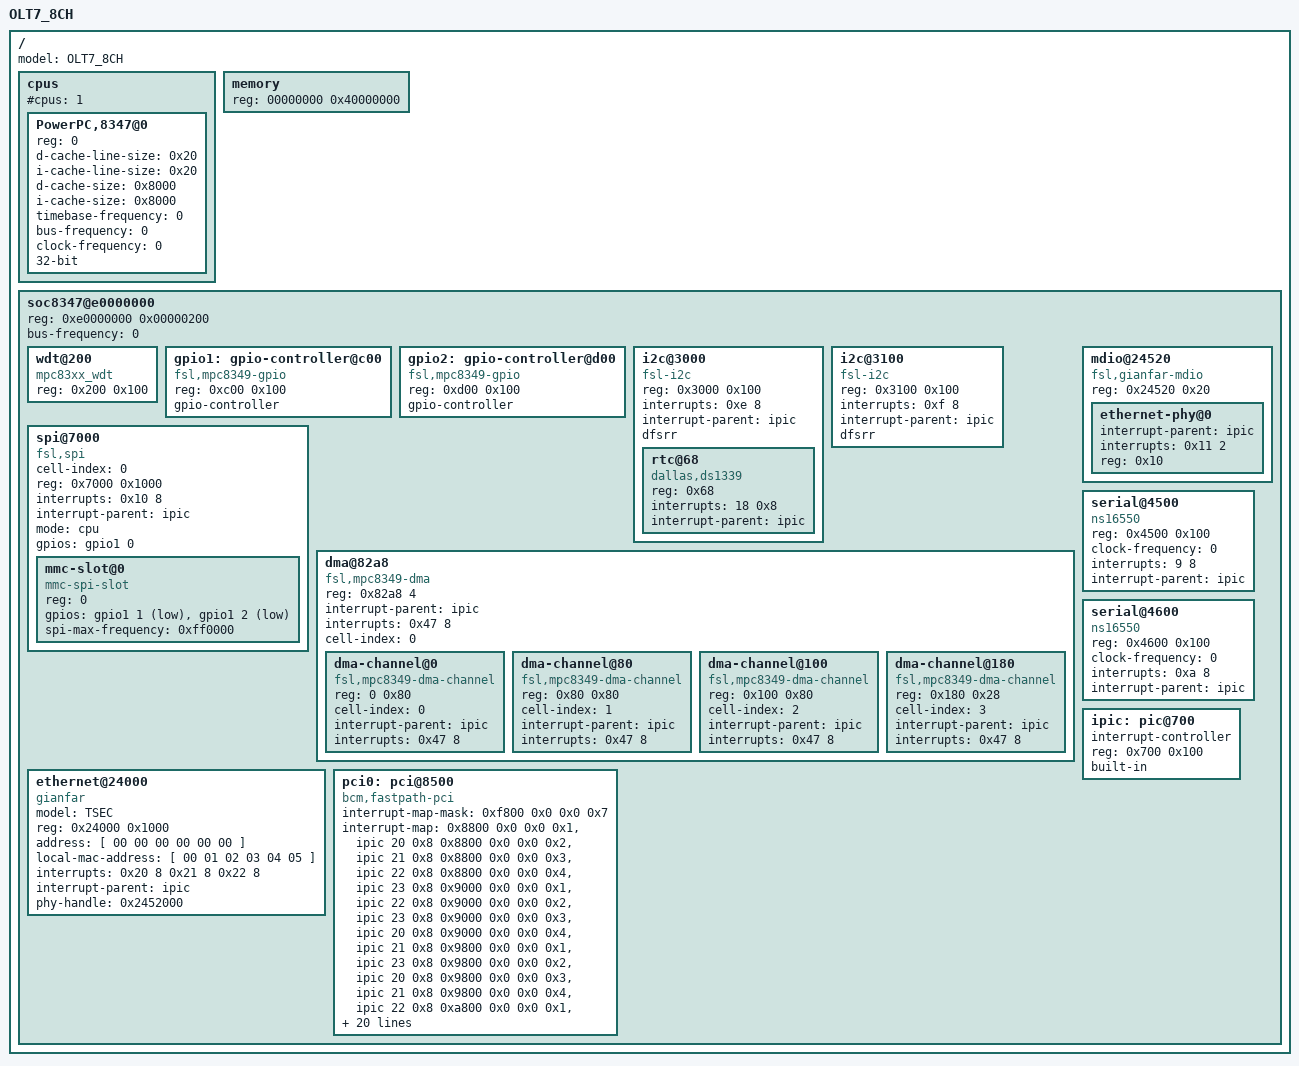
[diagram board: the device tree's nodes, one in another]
/*
 * OLT7_8CH Device Tree Source
 * Copyright 2011 PTInovacao,SA
 *
 * XXXX MPC8349E MDS Device Tree Source
 *
 * Copyright 2005, 2006 Freescale Semiconductor Inc.
 *
 * This program is free software; you can redistribute  it and/or modify it
 * under  the terms of  the GNU General  Public License as published by the
 * Free Software Foundation;  either version 2 of the  License, or (at your
 * option) any later version.
 */

 /dts-v1/;

/ {
	model = "OLT7_8CH";
//	compatible = "MPC834xMDS";
	#address-cells = <1>;
	#size-cells = <1>;

	cpus {
		#cpus = <1>;
		#address-cells = <1>;
		#size-cells = <0>;

		PowerPC,8347@0 {
			device_type = "cpu";
			reg = <0>;
			d-cache-line-size = <0x20>;	// 32 bytes
			i-cache-line-size = <0x20>;	// 32 bytes
			d-cache-size = <0x8000>;		// L1, 32K
			i-cache-size = <0x8000>;		// L1, 32K
			timebase-frequency = <0>;	// from bootloader
			bus-frequency = <0>;		// from bootloader
			clock-frequency = <0>;		// from bootloader
			32-bit;
		};
	};

	memory {
		device_type = "memory";
		reg = <00000000 0x40000000>;	// 512MB at 0
	};

	soc8347@e0000000 {
		#address-cells = <1>;
		#size-cells = <1>;
		#interrupt-cells = <2>;
		device_type = "soc";
		ranges = <0 0xe0000000 0x00100000>;
		reg = <0xe0000000 0x00000200>;
		bus-frequency = <0>;

		wdt@200 {
			device_type = "watchdog";
			compatible = "mpc83xx_wdt";
			reg = <0x200 0x100>;
		};

	        gpio1: gpio-controller@c00 {
                        #gpio-cells = <2>;
                        compatible = "fsl,mpc8349-gpio";
                        reg = <0xc00 0x100>;
//                        interrupts = <0x4a 8>;
//                        interrupt-parent = <&ipic>;
                        gpio-controller;
                };

                gpio2: gpio-controller@d00 {
                        #gpio-cells = <2>;
                        compatible = "fsl,mpc8349-gpio";
                        reg = <0xd00 0x100>;
//                        interrupts = <0x4b 8>;
//                        interrupt-parent = <&ipic>;
                        gpio-controller;
                };

		i2c@3000 {
			device_type = "i2c";
			compatible = "fsl-i2c";
			reg = <0x3000 0x100>;
			interrupts = <0xe 8>;
			interrupt-parent = <&ipic>;
			dfsrr;


			rtc@68 {
				device_type = "rtc";
				compatible = "dallas,ds1339";
				reg = <0x68>;
				interrupts = <18 0x8>;
				interrupt-parent = <&ipic>;
			};


		};

		i2c@3100 {
			device_type = "i2c";
			compatible = "fsl-i2c";
			reg = <0x3100 0x100>;
			interrupts = <0xf 8>;
			interrupt-parent = <&ipic>;
			dfsrr;

//			dtt@48 {
//                                compatible = "dallas,ds75";
//                                reg = <0x48>;
//                        };
		};

		spi@7000 {
			#address-cells = <1>;
            		#size-cells = <0>;
            		cell-index = <0>;  
			device_type = "spi";
			compatible = "fsl,spi";
			reg = <0x7000 0x1000>;
			interrupts = <0x10 8>;
			interrupt-parent = <&ipic>;
			mode = "cpu";
			gpios = <&gpio1 0 0>;
			mmc-slot@0 {
                                compatible = "mmc-spi-slot";
                                reg = <0>;
                                gpios = <&gpio1 1 1
                                         &gpio1 2 1>;
//                                voltage-ranges = <3300 3300>;
//                                spi-max-frequency = <2faf080>;
                                spi-max-frequency = <0xff0000>;
                        };

		};

		dma@82a8 {
			#address-cells = <1>;
			#size-cells = <1>;
			compatible = "fsl,mpc8349-dma", "fsl,elo-dma";
			reg = <0x82a8 4>;
			ranges = <0 0x8100 0x1a8>;
			interrupt-parent = <&ipic>;
			interrupts = <0x47 8>;
			cell-index = <0>;
			dma-channel@0 {
				compatible = "fsl,mpc8349-dma-channel", "fsl,elo-dma-channel";
				reg = <0 0x80>;
				cell-index = <0>;
				interrupt-parent = <&ipic>;
				interrupts = <0x47 8>;
			};
			dma-channel@80 {
				compatible = "fsl,mpc8349-dma-channel", "fsl,elo-dma-channel";
				reg = <0x80 0x80>;
				cell-index = <1>;
				interrupt-parent = <&ipic>;
				interrupts = <0x47 8>;
			};
			dma-channel@100 {
				compatible = "fsl,mpc8349-dma-channel", "fsl,elo-dma-channel";
				reg = <0x100 0x80>;
				cell-index = <2>;
				interrupt-parent = <&ipic>;
				interrupts = <0x47 8>;
			};
			dma-channel@180 {
				compatible = "fsl,mpc8349-dma-channel", "fsl,elo-dma-channel";
				reg = <0x180 0x28>;
				cell-index = <3>;
				interrupt-parent = <&ipic>;
				interrupts = <0x47 8>;
			};
		};


		/* phy type (ULPI or SERIAL) are only types supportted for MPH */
		/* port = 0 or 1 */
//		usb@22000 {
//			device_type = "usb";
//			compatible = "fsl-usb2-mph";
//			reg = <22000 1000>;
//			#address-cells = <1>;
//			#size-cells = <0>;
//			interrupt-parent = <700>;
//			interrupts = <27 2>;
//			phy_type = "ulpi";
//			port1;
//		};
//		/* phy type (ULPI, UTMI, UTMI_WIDE, SERIAL) */
//		usb@23000 {
//			device_type = "usb";
//			compatible = "fsl-usb2-dr";
//			reg = <23000 1000>;
//			#address-cells = <1>;
//			#size-cells = <0>;
//			interrupt-parent = <700>;
//			interrupts = <26 2>;
//			phy_type = "ulpi";
//		};

		mdio@24520 {
			device_type = "mdio";
			compatible = "fsl,gianfar-mdio";
			reg = <0x24520 0x20>;
			#address-cells = <1>;
			#size-cells = <0>;
			linux,phandle = <0x24520>;
			ethernet-phy@0 {
				linux,phandle = <0x2452000>;
				interrupt-parent = <&ipic>;
				interrupts = <0x11 2>;
				reg = <0x10>;
				device_type = "ethernet-phy";
			};
//			ethernet-phy@1 {
//				linux,phandle = <0x2452001>;
//				interrupt-parent = <&ipic>;
//				interrupts = <0x12 2>;
//				reg = <1>;
//				device_type = "ethernet-phy";
//			};
		};

		ethernet@24000 {
			device_type = "network";
			model = "TSEC";
			compatible = "gianfar";
			reg = <0x24000 0x1000>;
			address = [ 00 00 00 00 00 00 ];
			local-mac-address = [ 00 01 02 03 04 05 ];
			interrupts = <0x20 8 0x21 8 0x22 8>;
			interrupt-parent = <&ipic>;
			phy-handle = <0x2452000>;
		};

//		ethernet@25000 {
//			#address-cells = <1>;
//			#size-cells = <0>;
//			device_type = "network";
//			model = "TSEC";
//			compatible = "gianfar";
//			reg = <0x25000 0x1000>;
//			address = [ 00 00 00 00 00 00 ];
//			local-mac-address = [ 00 00 00 00 00 00 ];
//			interrupts = <0x23 8 0x24 8 0x25 8>;
//			interrupt-parent = <&ipic>;
//			phy-handle = <0x2452001>;
//		};

		serial@4500 {
			device_type = "serial";
			compatible = "ns16550";
			reg = <0x4500 0x100>;
			clock-frequency = <0>;
			interrupts = <9 8>;
			interrupt-parent = <&ipic>;
		};

		serial@4600 {
			device_type = "serial";
			compatible = "ns16550";
			reg = <0x4600 0x100>;
			clock-frequency = <0>;
			interrupts = <0xa 8>;
			interrupt-parent = <&ipic>;
		};

		pci0: pci@8500 {
			interrupt-map-mask = <0xf800 0x0 0x0 0x7>;
			interrupt-map = <
	
					/* IDSEL 0x11 */
					 0x8800 0x0 0x0 0x1 &ipic 20 0x8
					 0x8800 0x0 0x0 0x2 &ipic 21 0x8
					 0x8800 0x0 0x0 0x3 &ipic 22 0x8
					 0x8800 0x0 0x0 0x4 &ipic 23 0x8
	
					/* IDSEL 0x12 */
					 0x9000 0x0 0x0 0x1 &ipic 22 0x8
					 0x9000 0x0 0x0 0x2 &ipic 23 0x8
					 0x9000 0x0 0x0 0x3 &ipic 20 0x8
					 0x9000 0x0 0x0 0x4 &ipic 21 0x8
	
					/* IDSEL 0x13 */
					 0x9800 0x0 0x0 0x1 &ipic 23 0x8
					 0x9800 0x0 0x0 0x2 &ipic 20 0x8
					 0x9800 0x0 0x0 0x3 &ipic 21 0x8
					 0x9800 0x0 0x0 0x4 &ipic 22 0x8
	
					/* IDSEL 0x15 */
					 0xa800 0x0 0x0 0x1 &ipic 20 0x8
					 0xa800 0x0 0x0 0x2 &ipic 21 0x8
					 0xa800 0x0 0x0 0x3 &ipic 22 0x8
					 0xa800 0x0 0x0 0x4 &ipic 23 0x8
	
					/* IDSEL 0x16 */
					 0xb000 0x0 0x0 0x1 &ipic 23 0x8
					 0xb000 0x0 0x0 0x2 &ipic 20 0x8
					 0xb000 0x0 0x0 0x3 &ipic 21 0x8
					 0xb000 0x0 0x0 0x4 &ipic 22 0x8
	
					/* IDSEL 0x17 */
					 0xb800 0x0 0x0 0x1 &ipic 22 0x8
					 0xb800 0x0 0x0 0x2 &ipic 23 0x8
					 0xb800 0x0 0x0 0x3 &ipic 20 0x8
					 0xb800 0x0 0x0 0x4 &ipic 21 0x8
	
					/* IDSEL 0x18 */
					 0xc000 0x0 0x0 0x1 &ipic 21 0x8
					 0xc000 0x0 0x0 0x2 &ipic 22 0x8
					 0xc000 0x0 0x0 0x3 &ipic 23 0x8
					 0xc000 0x0 0x0 0x4 &ipic 20 0x8>;
			interrupt-parent = <&ipic>;
			interrupts = <48 0x8>;
			bus-range = <0 0>;
//			ranges = <0x02000000 0x0 0x90000000 0x90000000 0x0 0x10000000
//				  0x42000000 0x0 0x80000000 0x80000000 0x0 0x10000000
//				  0x01000000 0x0 0x00000000 0xe2000000 0x0 0x00100000>;
			clock-frequency = <66666666>;
			#interrupt-cells = <1>;
			#size-cells = <2>;
			#address-cells = <3>;
			reg = <0x8500 0x100		/* internal registers */
			       0x8300 0x8>;		/* config space access registers */
			compatible = "bcm,fastpath-pci","fsl,mpc8349-pci";
			device_type = "pci";
		};

//		pci1: pci@e0008600 {
//			interrupt-map-mask = <0xf800 0x0 0x0 0x7>;
//			interrupt-map = <
//	
//					/* IDSEL 0x11 */
//					 0x8800 0x0 0x0 0x1 &ipic 20 0x8
//					 0x8800 0x0 0x0 0x2 &ipic 21 0x8
//					 0x8800 0x0 0x0 0x3 &ipic 22 0x8
//					 0x8800 0x0 0x0 0x4 &ipic 23 0x8
//	
//					/* IDSEL 0x12 */
//					 0x9000 0x0 0x0 0x1 &ipic 22 0x8
//					 0x9000 0x0 0x0 0x2 &ipic 23 0x8
//					 0x9000 0x0 0x0 0x3 &ipic 20 0x8
//					 0x9000 0x0 0x0 0x4 &ipic 21 0x8
//	
//					/* IDSEL 0x13 */
//					 0x9800 0x0 0x0 0x1 &ipic 23 0x8
//					 0x9800 0x0 0x0 0x2 &ipic 20 0x8
//					 0x9800 0x0 0x0 0x3 &ipic 21 0x8
//					 0x9800 0x0 0x0 0x4 &ipic 22 0x8
//	
//					/* IDSEL 0x15 */
//					 0xa800 0x0 0x0 0x1 &ipic 20 0x8
//					 0xa800 0x0 0x0 0x2 &ipic 21 0x8
//					 0xa800 0x0 0x0 0x3 &ipic 22 0x8
//					 0xa800 0x0 0x0 0x4 &ipic 23 0x8
//	
//					/* IDSEL 0x16 */
//					 0xb000 0x0 0x0 0x1 &ipic 23 0x8
//					 0xb000 0x0 0x0 0x2 &ipic 20 0x8
//					 0xb000 0x0 0x0 0x3 &ipic 21 0x8
//					 0xb000 0x0 0x0 0x4 &ipic 22 0x8
//	
//					/* IDSEL 0x17 */
//					 0xb800 0x0 0x0 0x1 &ipic 22 0x8
//					 0xb800 0x0 0x0 0x2 &ipic 23 0x8
//					 0xb800 0x0 0x0 0x3 &ipic 20 0x8
//					 0xb800 0x0 0x0 0x4 &ipic 21 0x8
//	
//					/* IDSEL 0x18 */
//					 0xc000 0x0 0x0 0x1 &ipic 21 0x8
//					 0xc000 0x0 0x0 0x2 &ipic 22 0x8
//					 0xc000 0x0 0x0 0x3 &ipic 23 0x8
//					 0xc000 0x0 0x0 0x4 &ipic 20 0x8>;
//			interrupt-parent = <&ipic>;
//			interrupts = <67 0x8>;
//			bus-range = <0 0>;
//			ranges = <0x02000000 0x0 0xb0000000 0xb0000000 0x0 0x10000000
//				  0x42000000 0x0 0xa0000000 0xa0000000 0x0 0x10000000
//				  0x01000000 0x0 0x00000000 0xe2100000 0x0 0x00100000>;
//			clock-frequency = <66666666>;
//			#interrupt-cells = <1>;
//			#size-cells = <2>;
//			#address-cells = <3>;
//			reg = <0xe0008600 0x100		/* internal registers */
//			       0xe0008380 0x8>;		/* config space access registers */
//			compatible = "fsl,mpc8349-pci";
//			device_type = "pci";
//		};

		/* May need to remove if on a part without crypto engine */
//		crypto@30000 {
//			device_type = "crypto";
//			model = "SEC2";
//			compatible = "talitos";
//			reg = <30000 10000>;
//			interrupts = <b 8>;
//			interrupt-parent = <700>;
//			num-channels = <4>;
//			channel-fifo-len = <18>;
//			exec-units-mask = <0000007e>;
//			/* desc mask is for rev2.0,
//			 * we need runtime fixup for >2.0 */
//			descriptor-types-mask = <01010ebf>;
//		};

		/* IPIC
		 * interrupts cell = <intr #, sense>
		 * sense values match linux IORESOURCE_IRQ_* defines:
		 * sense == 8: Level, low assertion
		 * sense == 2: Edge, high-to-low change
		 */
		ipic: pic@700 {
			linux,phandle = <0x700>;
			interrupt-controller;
			#address-cells = <0>;
			#interrupt-cells = <2>;
			reg = <0x700 0x100>;
			built-in;
			device_type = "ipic";
		};

	};
};
